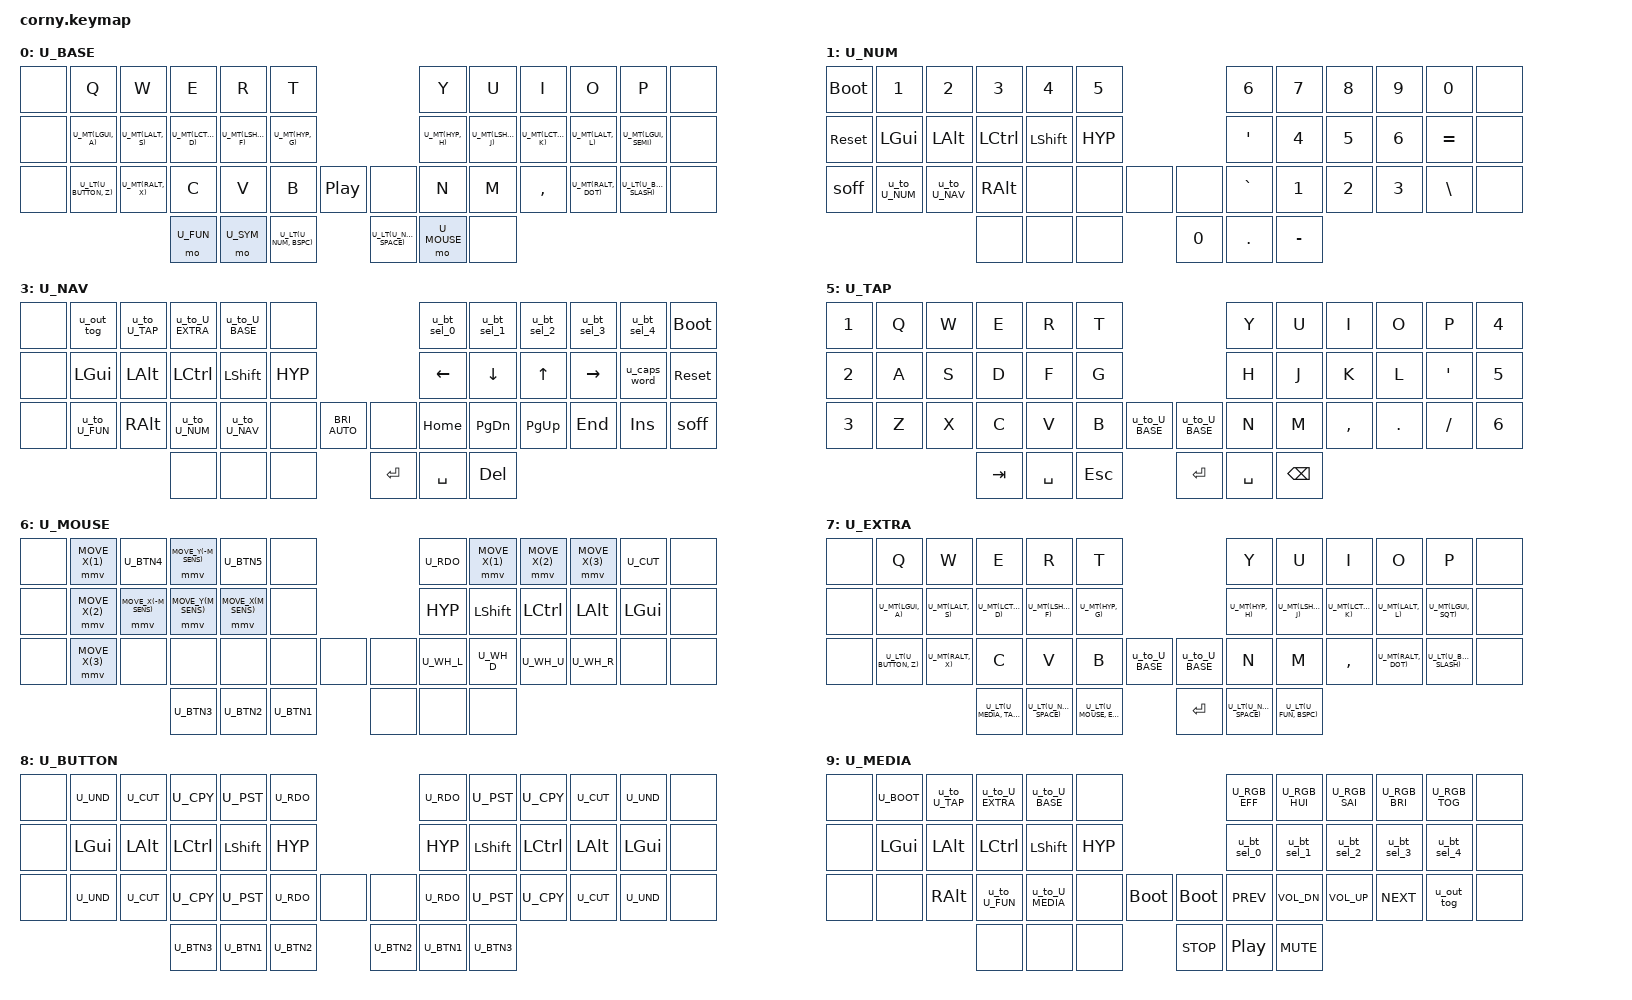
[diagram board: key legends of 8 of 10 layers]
#include <behaviors.dtsi>
#include <behaviors/mouse_key_press.dtsi>
#if defined (MIRYOKU_KLUDGE_MOUSEKEYSPR)
  #include <behaviors/mouse_move.dtsi>
  #include <behaviors/mouse_scroll.dtsi>
#endif
#include <dt-bindings/zmk/keys.h>
#include <dt-bindings/zmk/bt.h>
#include <dt-bindings/zmk/rgb.h>
#include <dt-bindings/zmk/outputs.h>
#include <dt-bindings/zmk/ext_power.h>
#include <dt-bindings/zmk/mouse.h>

#define U_TAPPING_TERM 200

#define U_MACRO_VA_ARGS(macro, ...) macro(__VA_ARGS__)
#define U_STRINGIFY(x) #x
#define U_MACRO(name,...) \
/ { \
  macros { \
    name: name { \
      compatible = "zmk,behavior-macro"; \
      #binding-cells = <0>; \
      __VA_ARGS__ \
    }; \
  }; \
};


#include "../../../miryoku_behaviors/miryoku_babel/miryoku_layer_list.h"
#include "../../../miryoku_behaviors/miryoku_clipboard.h"
#include "../../../miryoku_behaviors/miryoku_double_tap_guard.dtsi"
#include "../../../miryoku_behaviors/miryoku_double_tap_guard.h"
#include "../../../miryoku_behaviors/miryoku_shift_functions.h"
#include "../../../miryoku_behaviors/miryoku_shift_functions.dtsi"
#include "../../../miryoku_behaviors/miryoku_kludge_mousekeyspr.h"
#include "../../../miryoku_behaviors/miryoku_behaviors.dtsi"
#include "../../../miryoku_behaviors/miryoku_behaviors.h"
#include "../../../miryoku_behaviors/combos.dtsi"

#define U_NP &none // key is not present
#define U_NA &none // present but not available for use
#define U_NU &none // available but not used
#define M_SENS 900
#define MOUSE_UP &mmv MOVE_Y(-M_SENS)
#define MOUSE_DN &mmv MOVE_Y(M_SENS)
#define MOUSE_LF &mmv MOVE_X(-M_SENS)
#define MOUSE_RT &mmv MOVE_X(M_SENS)
#define MOUSE_FST &mmv MOVE_X(3)
#define MOUSE_SLW &mmv MOVE_X(1)
#define MOUSE_NRML &mmv MOVE_X(2)

/ {
    keymap {
        compatible = "zmk,keymap";

        U_BASE {
            bindings = <
                U_NU &kp Q             &kp W         &kp E            &kp R              &kp T                              &kp Y              &kp U              &kp I          &kp O           &kp P                 U_NU
                U_NU U_MT(LGUI, A)     U_MT(LALT, S) U_MT(LCTRL, D)   U_MT(LSHFT, F)     U_MT(HYP, G)                       U_MT(HYP, H)       U_MT(LSHFT, J)     U_MT(LCTRL, K) U_MT(LALT, L)   U_MT(LGUI, SEMI)      U_NU
                U_NU U_LT(U_BUTTON, Z) U_MT(RALT, X) &kp C            &kp V              &kp B             &kp C_PP    U_NU &kp N              &kp M              &kp COMMA      U_MT(RALT, DOT) U_LT(U_BUTTON, SLASH) U_NU
                                                    &mo U_FUN &mo U_SYM   U_LT(U_NUM, BSPC)                  U_LT(U_NAV, SPACE) &mo U_MOUSE U_NU
            >;
            sensor-bindings = <
                &inc_dec_kp C_VOL_UP C_VOL_DN &inc_dec_kp UP DOWN
            >;
        };

        U_NUM {
            bindings = <
                &bootloader &kp N1       &kp N2        &kp N3      &kp N4    &kp N5               &kp N6    &kp N7  &kp N8  &kp N9    &kp N0    U_NU
                &sys_reset  &kp LGUI     &kp LALT      &kp LCTRL   &kp LSHFT &kp HYP              &kp SQT   &kp N4  &kp N5  &kp N6    &kp EQUAL U_NU
                &soff       &u_to_U_NUM  &u_to_U_NAV   &kp RALT    U_NA      U_NU    U_NU    U_NU &kp GRAVE &kp N1  &kp N2  &kp N3    &kp BSLH  U_NU
                                                       U_NA        U_NA      U_NA                 &kp N0    &kp DOT &kp MINUS
            >;
            sensor-bindings = <
                &inc_dec_kp C_VOL_UP C_VOL_DN &inc_dec_kp LEFT RIGHT
            >;
        };

        U_SYM {
            bindings = <
                U_NA &u_to_U_BASE &u_to_U_EXTRA &u_to_U_TAP U_BOOT    U_NU                 &kp LBRC  &kp AMPS &kp ASTRK &kp LPAR  &kp RBRC U_NU
                U_NA &kp LGUI     &kp LALT      &kp LCTRL   &kp LSHFT &kp HYP              &kp DQT   &kp DLLR &kp PRCNT &kp CARET &kp PLUS U_NU
                U_NA &u_to_U_SYM  &u_to_U_MOUSE &kp RALT    U_NA      U_NU    U_NU    U_NU &kp TILDE &kp EXCL &kp AT    &kp HASH  &kp PIPE U_NU
                                                U_NA        U_NA      U_NA                 &kp UNDER &kp LPAR &kp RPAR
            >;
            sensor-bindings = <
                &inc_dec_kp C_VOL_UP C_VOL_DN &inc_dec_kp UP DOWN
            >;
        };
        U_NAV {
            bindings = <
                U_NU &u_out_tog  &u_to_U_TAP &u_to_U_EXTRA &u_to_U_BASE U_NA                           &u_bt_sel_0 &u_bt_sel_1 &u_bt_sel_2 &u_bt_sel_3 &u_bt_sel_4  &bootloader
                U_NU &kp LGUI    &kp LALT    &kp LCTRL     &kp LSHFT    &kp HYP                        &kp LEFT    &kp DOWN    &kp UP      &kp RIGHT   &u_caps_word &sys_reset
                U_NU &u_to_U_FUN &kp RALT    &u_to_U_NUM   &u_to_U_NAV  U_NA    &kp C_BRI_AUTO    U_NA &kp HOME    &kp PG_DN   &kp PG_UP   &kp END     &kp INS      &soff
                                             U_NA          U_NA         U_NA                           &kp RET     &kp SPACE   &kp DEL
            >;
            sensor-bindings = <
                &inc_dec_kp C_BRI_UP C_BRI_DN &inc_dec_kp UP DOWN
            >;
        };
        U_FUN {
            bindings = <
                U_NU &u_to_U_BASE &u_to_U_EXTRA &u_to_U_TAP U_BOOT    U_NU                 &kp PSCRN       &kp F7    &kp F8    &kp F9    &kp F10 U_NA
                U_NU &kp LGUI     &kp LALT      &kp LCTRL   &kp LSHFT &kp HYP              &kp SLCK        &kp F4    &kp F5    &kp F6    &kp F11 U_NA
                U_NU &u_to_U_FUN  &u_to_U_MEDIA &kp RALT    U_NA      U_NU    U_NU    U_NU &kp PAUSE_BREAK &kp F1    &kp F2    &kp F3    &kp F12 U_NA
                                                U_NA        U_NA      U_NA                 &kp K_APP       &kp SPACE &kp BSPC
            >;
            sensor-bindings = <
                &inc_dec_kp C_VOL_UP C_VOL_DN &inc_dec_kp PG_UP PG_DN
            >;
        };
        U_TAP  {
            bindings = <
                &kp N1 &kp Q &kp W &kp E   &kp R     &kp T                             &kp Y   &kp U     &kp I     &kp O   &kp P     &kp N4
                &kp N2 &kp A &kp S &kp D   &kp F     &kp G                             &kp H   &kp J     &kp K     &kp L   &kp SQT   &kp N5
                &kp N3 &kp Z &kp X &kp C   &kp V     &kp B   &u_to_U_BASE &u_to_U_BASE &kp N   &kp M     &kp COMMA &kp DOT &kp SLASH &kp N6
                                   &kp TAB &kp SPACE &kp ESC                           &kp RET &kp SPACE &kp BSPC
            >;
        };
        U_MOUSE {
            bindings = <
                U_NU MOUSE_SLW  U_BTN4   MOUSE_UP U_BTN5   U_NA             U_RDO   MOUSE_SLW MOUSE_NRML MOUSE_FST U_CUT    U_NU
                U_NU MOUSE_NRML MOUSE_LF MOUSE_DN MOUSE_RT U_NA             &kp HYP &kp LSHFT &kp LCTRL  &kp LALT  &kp LGUI U_NU
                U_NU MOUSE_FST  U_NA     U_NA     U_NA     U_NA   U_NU U_NU U_WH_L  U_WH_D    U_WH_U     U_WH_R    U_NU     U_NU
                                         U_BTN3   U_BTN2   U_BTN1           U_NA    U_NA      U_NA                 
            >;
            sensor-bindings = <
                &inc_dec_kp C_VOL_UP C_VOL_DN &inc_dec_kp PG_UP PG_DN
            >;
        };


        U_EXTRA {
            bindings = <
                U_NU &kp Q             &kp W         &kp E              &kp R              &kp T                                        &kp Y        &kp U              &kp I             &kp O           &kp P                 U_NU
                U_NU U_MT(LGUI, A)     U_MT(LALT, S) U_MT(LCTRL, D)     U_MT(LSHFT, F)     U_MT(HYP, G)                                 U_MT(HYP, H) U_MT(LSHFT, J)     U_MT(LCTRL, K)    U_MT(LALT, L)   U_MT(LGUI, SQT)       U_NU
                U_NU U_LT(U_BUTTON, Z) U_MT(RALT, X) &kp C              &kp V              &kp B              &u_to_U_BASE &u_to_U_BASE &kp N        &kp M              &kp COMMA         U_MT(RALT, DOT) U_LT(U_BUTTON, SLASH) U_NU
                                                     U_LT(U_MEDIA, TAB) U_LT(U_NUM, SPACE) U_LT(U_MOUSE, ESC)                           &kp RET      U_LT(U_NAV, SPACE) U_LT(U_FUN, BSPC)
            >;
            sensor-bindings = <
                &inc_dec_kp C_VOL_UP C_VOL_DN &inc_dec_kp UP DOWN
            >;
        };

        U_BUTTON {
            bindings = <
                U_NU U_UND    U_CUT    U_CPY     U_PST     U_RDO                U_RDO   U_PST     U_CPY     U_CUT    U_UND    U_NU
                U_NU &kp LGUI &kp LALT &kp LCTRL &kp LSHFT &kp HYP              &kp HYP &kp LSHFT &kp LCTRL &kp LALT &kp LGUI U_NU
                U_NU U_UND    U_CUT    U_CPY     U_PST     U_RDO   U_NU    U_NU U_RDO   U_PST     U_CPY     U_CUT    U_UND    U_NU
                                       U_BTN3    U_BTN1    U_BTN2               U_BTN2  U_BTN1    U_BTN3
            >;
            sensor-bindings = <
                &inc_dec_kp C_VOL_UP C_VOL_DN &inc_dec_kp UP DOWN
            >;
        };


        U_MEDIA {
            bindings = <
                U_NU U_BOOT   &u_to_U_TAP &u_to_U_EXTRA &u_to_U_BASE  U_NA                            U_RGB_EFF   U_RGB_HUI    U_RGB_SAI    U_RGB_BRI   U_RGB_TOG   U_NU
                U_NU &kp LGUI &kp LALT    &kp LCTRL     &kp LSHFT     &kp HYP                         &u_bt_sel_0 &u_bt_sel_1  &u_bt_sel_2  &u_bt_sel_3 &u_bt_sel_4 U_NU
                U_NU U_NA     &kp RALT    &u_to_U_FUN   &u_to_U_MEDIA U_NA    &bootloader &bootloader &kp C_PREV  &kp C_VOL_DN &kp C_VOL_UP &kp C_NEXT  &u_out_tog  U_NU
                                          U_NA          U_NA          U_NA                            &kp C_STOP  &kp C_PP     &kp C_MUTE
            >;
            sensor-bindings = <
                &inc_dec_kp C_VOL_UP C_VOL_DN &inc_dec_kp UP DOWN
            >;
        };
    };
};
